AUTOSAR XML (schema 00047)
package /ComponentTypes
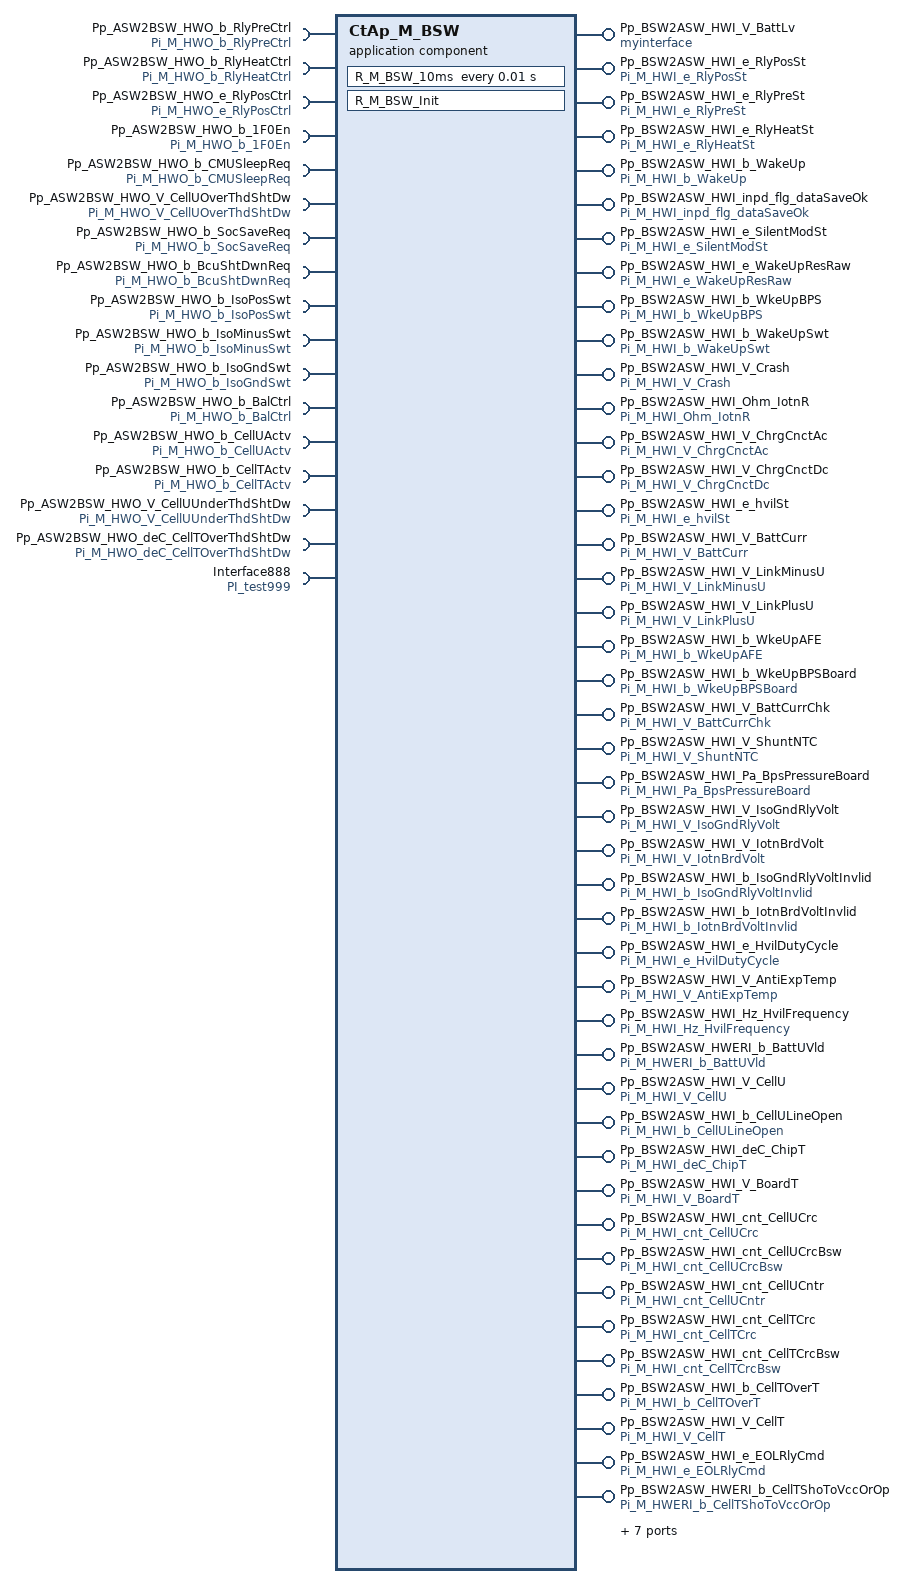
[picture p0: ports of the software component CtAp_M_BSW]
  application sw component type CtAp_M_BSW
    51 x provide port:
      Pp_BSW2ASW_HWI_V_BattLv: nonqueued-sender-com-spec{data-element=HWI_V_BattLv, init-value=123.0}, provided-interface=myinterface
      Pp_BSW2ASW_HWI_e_RlyPosSt: nonqueued-sender-com-spec{data-element=HWI_e_RlyPosSt, init-value=456}, provided-interface=Pi_M_HWI_e_RlyPosSt
      Pp_BSW2ASW_HWI_e_RlyPreSt: nonqueued-sender-com-spec{data-element=HWI_e_RlyPreSt, init-value=0}, provided-interface=Pi_M_HWI_e_RlyPreSt
      Pp_BSW2ASW_HWI_e_RlyHeatSt: nonqueued-sender-com-spec{data-element=HWI_e_RlyHeatSt, init-value=0}, provided-interface=Pi_M_HWI_e_RlyHeatSt
      Pp_BSW2ASW_HWI_b_WakeUp: nonqueued-sender-com-spec{data-element=HWI_b_WakeUp, init-value=0}, provided-interface=Pi_M_HWI_b_WakeUp
      Pp_BSW2ASW_HWI_inpd_flg_dataSaveOk: nonqueued-sender-com-spec{data-element=HWI_inpd_flg_dataSaveOk, init-value=0}, provided-interface=Pi_M_HWI_inpd_flg_dataSaveOk
      Pp_BSW2ASW_HWI_e_SilentModSt: nonqueued-sender-com-spec{data-element=HWI_e_SilentModSt, init-value=0}, provided-interface=Pi_M_HWI_e_SilentModSt
      Pp_BSW2ASW_HWI_e_WakeUpResRaw: nonqueued-sender-com-spec{data-element=HWI_e_WakeUpResRaw, init-value=0}, provided-interface=Pi_M_HWI_e_WakeUpResRaw
      Pp_BSW2ASW_HWI_b_WkeUpBPS: nonqueued-sender-com-spec{data-element=HWI_b_WkeUpBPS, init-value=0}, provided-interface=Pi_M_HWI_b_WkeUpBPS
      Pp_BSW2ASW_HWI_b_WakeUpSwt: nonqueued-sender-com-spec{data-element=HWI_b_WakeUpSwt, init-value=0}, provided-interface=Pi_M_HWI_b_WakeUpSwt
      Pp_BSW2ASW_HWI_V_Crash: nonqueued-sender-com-spec{data-element=HWI_V_Crash, init-value=0.0}, provided-interface=Pi_M_HWI_V_Crash
      Pp_BSW2ASW_HWI_Ohm_IotnR: nonqueued-sender-com-spec{data-element=HWI_Ohm_IotnR, init-value=0}, provided-interface=Pi_M_HWI_Ohm_IotnR
      Pp_BSW2ASW_HWI_V_ChrgCnctAc: nonqueued-sender-com-spec{data-element=HWI_V_ChrgCnctAc, init-value=0.0}, provided-interface=Pi_M_HWI_V_ChrgCnctAc
      Pp_BSW2ASW_HWI_V_ChrgCnctDc: nonqueued-sender-com-spec{data-element=HWI_V_ChrgCnctDc, init-value=0.0}, provided-interface=Pi_M_HWI_V_ChrgCnctDc
      Pp_BSW2ASW_HWI_e_hvilSt: nonqueued-sender-com-spec{data-element=HWI_e_hvilSt, init-value=0}, provided-interface=Pi_M_HWI_e_hvilSt
      Pp_BSW2ASW_HWI_V_BattCurr: nonqueued-sender-com-spec{data-element=HWI_V_BattCurr, init-value=0.0}, provided-interface=Pi_M_HWI_V_BattCurr
      Pp_BSW2ASW_HWI_V_LinkMinusU: nonqueued-sender-com-spec{data-element=HWI_V_LinkMinusU, init-value=0.0}, provided-interface=Pi_M_HWI_V_LinkMinusU
      Pp_BSW2ASW_HWI_V_LinkPlusU: nonqueued-sender-com-spec{data-element=HWI_V_LinkPlusU, init-value=0.0}, provided-interface=Pi_M_HWI_V_LinkPlusU
      Pp_BSW2ASW_HWI_b_WkeUpAFE: nonqueued-sender-com-spec{data-element=HWI_b_WkeUpAFE, init-value=0}, provided-interface=Pi_M_HWI_b_WkeUpAFE
      Pp_BSW2ASW_HWI_b_WkeUpBPSBoard: nonqueued-sender-com-spec{data-element=HWI_b_WkeUpBPSBoard, init-value=0}, provided-interface=Pi_M_HWI_b_WkeUpBPSBoard
      Pp_BSW2ASW_HWI_V_BattCurrChk: nonqueued-sender-com-spec{data-element=HWI_V_BattCurrChk, init-value=0.0}, provided-interface=Pi_M_HWI_V_BattCurrChk
      Pp_BSW2ASW_HWI_V_ShuntNTC: nonqueued-sender-com-spec{data-element=HWI_V_ShuntNTC, init-value=0.0}, provided-interface=Pi_M_HWI_V_ShuntNTC
      Pp_BSW2ASW_HWI_Pa_BpsPressureBoard: nonqueued-sender-com-spec{data-element=HWI_Pa_BpsPressureBoard, init-value=0.0}, provided-interface=Pi_M_HWI_Pa_BpsPressureBoard
      Pp_BSW2ASW_HWI_V_IsoGndRlyVolt: nonqueued-sender-com-spec{data-element=HWI_V_IsoGndRlyVolt, init-value=0.0}, provided-interface=Pi_M_HWI_V_IsoGndRlyVolt
      Pp_BSW2ASW_HWI_V_IotnBrdVolt: nonqueued-sender-com-spec{data-element=HWI_V_IotnBrdVolt, init-value=0.0}, provided-interface=Pi_M_HWI_V_IotnBrdVolt
      Pp_BSW2ASW_HWI_b_IsoGndRlyVoltInvlid: nonqueued-sender-com-spec{data-element=HWI_b_IsoGndRlyVoltInvlid, init-value=0}, provided-interface=Pi_M_HWI_b_IsoGndRlyVoltInvlid
      Pp_BSW2ASW_HWI_b_IotnBrdVoltInvlid: nonqueued-sender-com-spec{data-element=HWI_b_IotnBrdVoltInvlid, init-value=0}, provided-interface=Pi_M_HWI_b_IotnBrdVoltInvlid
      Pp_BSW2ASW_HWI_e_HvilDutyCycle: nonqueued-sender-com-spec{data-element=HWI_e_HvilDutyCycle, init-value=0}, provided-interface=Pi_M_HWI_e_HvilDutyCycle
      Pp_BSW2ASW_HWI_V_AntiExpTemp: nonqueued-sender-com-spec{data-element=HWI_V_AntiExpTemp, init-value=0.0}, provided-interface=Pi_M_HWI_V_AntiExpTemp
      Pp_BSW2ASW_HWI_Hz_HvilFrequency: nonqueued-sender-com-spec{data-element=HWI_Hz_HvilFrequency, init-value=0}, provided-interface=Pi_M_HWI_Hz_HvilFrequency
      Pp_BSW2ASW_HWERI_b_BattUVld: nonqueued-sender-com-spec{data-element=HWERI_b_BattUVld, init-value=0}, provided-interface=Pi_M_HWERI_b_BattUVld
      Pp_BSW2ASW_HWI_V_CellU: nonqueued-sender-com-spec{data-element=HWI_V_CellU, init-value=208 x 11111}, provided-interface=Pi_M_HWI_V_CellU
      Pp_BSW2ASW_HWI_b_CellULineOpen: nonqueued-sender-com-spec{data-element=HWI_b_CellULineOpen, init-value=208 x 22222}, provided-interface=Pi_M_HWI_b_CellULineOpen
      Pp_BSW2ASW_HWI_deC_ChipT: nonqueued-sender-com-spec{data-element=HWI_deC_ChipT, init-value=13 x 33333}, provided-interface=Pi_M_HWI_deC_ChipT
      Pp_BSW2ASW_HWI_V_BoardT: nonqueued-sender-com-spec{data-element=HWI_V_BoardT, init-value=26 x 0}, provided-interface=Pi_M_HWI_V_BoardT
      Pp_BSW2ASW_HWI_cnt_CellUCrc: nonqueued-sender-com-spec{data-element=HWI_cnt_CellUCrc, init-value=208 x 0}, provided-interface=Pi_M_HWI_cnt_CellUCrc
      Pp_BSW2ASW_HWI_cnt_CellUCrcBsw: nonqueued-sender-com-spec{data-element=HWI_cnt_CellUCrcBsw, init-value=208 x 0}, provided-interface=Pi_M_HWI_cnt_CellUCrcBsw
      Pp_BSW2ASW_HWI_cnt_CellUCntr: nonqueued-sender-com-spec{data-element=HWI_cnt_CellUCntr, init-value=208 x 0}, provided-interface=Pi_M_HWI_cnt_CellUCntr
      Pp_BSW2ASW_HWI_cnt_CellTCrc: nonqueued-sender-com-spec{data-element=HWI_cnt_CellTCrc, init-value=78 x 0}, provided-interface=Pi_M_HWI_cnt_CellTCrc
      Pp_BSW2ASW_HWI_cnt_CellTCrcBsw: nonqueued-sender-com-spec{data-element=HWI_cnt_CellTCrcBsw, init-value=78 x 0}, provided-interface=Pi_M_HWI_cnt_CellTCrcBsw
      Pp_BSW2ASW_HWI_b_CellTOverT: nonqueued-sender-com-spec{data-element=HWI_b_CellTOverT, init-value=78 x 0}, provided-interface=Pi_M_HWI_b_CellTOverT
      Pp_BSW2ASW_HWI_V_CellT: nonqueued-sender-com-spec{data-element=HWI_V_CellT, init-value=78 x 0}, provided-interface=Pi_M_HWI_V_CellT
      Pp_BSW2ASW_HWI_e_EOLRlyCmd: nonqueued-sender-com-spec{data-element=HWI_e_EOLRlyCmd, init-value=8 x 0}, provided-interface=Pi_M_HWI_e_EOLRlyCmd
      Pp_BSW2ASW_HWERI_b_CellTShoToVccOrOp: nonqueued-sender-com-spec{data-element=HWERI_b_CellTShoToVccOrOp, init-value=78 x 0}, provided-interface=Pi_M_HWERI_b_CellTShoToVccOrOp
      Pp_BSW2ASW_HWERI_b_CellTShoToGnd: nonqueued-sender-com-spec{data-element=HWERI_b_CellTShoToGnd, init-value=78 x 0}, provided-interface=Pi_M_HWERI_b_CellTShoToGnd
      Pp_BSW2ASW_HWERI_b_CellBalErr: nonqueued-sender-com-spec{data-element=HWERI_b_CellBalErr, init-value=208 x 0}, provided-interface=Pi_M_HWERI_b_CellBalErr
      Pp_BSW2ASW_HWERI_b_CellUOverU: nonqueued-sender-com-spec{data-element=HWERI_b_CellUOverU, init-value=208 x 0}, provided-interface=Pi_M_HWERI_b_CellUOverU
      Pp_BSW2ASW_HWERI_b_CellUUnderU: nonqueued-sender-com-spec{data-element=HWERI_b_CellUUnderU, init-value=208 x 0}, provided-interface=Pi_M_HWERI_b_CellUUnderU
      Pp_BSW2ASW_HWERI_b_ChipComErr: nonqueued-sender-com-spec{data-element=HWERI_b_ChipComErr, init-value=13 x 0}, provided-interface=Pi_M_HWERI_b_ChipComErr
      Pp_BSW2ASW_HWERI_b_SysRstErr: nonqueued-sender-com-spec{data-element=HWERI_b_SysRstErr, init-value=13 x 0}, provided-interface=Pi_M_HWERI_b_SysRstErr
      Pp_BSW2ASW_AccRateType: nonqueued-sender-com-spec{data-element=AccRateType, init-value=fields=[fields=[99.99, 99.99, 99.99], fields=[99.99, 99.99, 99.99]]}, provided-interface=Pi_M_AccRateType
    17 x require port:
      Pp_ASW2BSW_HWO_b_RlyPreCtrl: nonqueued-receiver-com-spec{data-element=HWO_b_RlyPreCtrl, filter=data-filter-type=ALWAYS}, required-interface=Pi_M_HWO_b_RlyPreCtrl
      Pp_ASW2BSW_HWO_b_RlyHeatCtrl: nonqueued-receiver-com-spec{data-element=HWO_b_RlyHeatCtrl, filter=data-filter-type=ALWAYS}, required-interface=Pi_M_HWO_b_RlyHeatCtrl
      Pp_ASW2BSW_HWO_e_RlyPosCtrl: nonqueued-receiver-com-spec{data-element=HWO_e_RlyPosCtrl, filter=data-filter-type=ALWAYS}, required-interface=Pi_M_HWO_e_RlyPosCtrl
      Pp_ASW2BSW_HWO_b_1F0En: nonqueued-receiver-com-spec{data-element=HWO_b_1F0En, filter=data-filter-type=ALWAYS}, required-interface=Pi_M_HWO_b_1F0En
      Pp_ASW2BSW_HWO_b_CMUSleepReq: nonqueued-receiver-com-spec{data-element=HWO_b_CMUSleepReq, filter=data-filter-type=ALWAYS}, required-interface=Pi_M_HWO_b_CMUSleepReq
      Pp_ASW2BSW_HWO_V_CellUOverThdShtDw: nonqueued-receiver-com-spec{data-element=HWO_V_CellUOverThdShtDw, filter=data-filter-type=ALWAYS}, required-interface=Pi_M_HWO_V_CellUOverThdShtDw
      Pp_ASW2BSW_HWO_b_SocSaveReq: nonqueued-receiver-com-spec{data-element=HWO_b_SocSaveReq, filter=data-filter-type=ALWAYS}, required-interface=Pi_M_HWO_b_SocSaveReq
      Pp_ASW2BSW_HWO_b_BcuShtDwnReq: nonqueued-receiver-com-spec{data-element=HWO_b_BcuShtDwnReq, filter=data-filter-type=ALWAYS}, required-interface=Pi_M_HWO_b_BcuShtDwnReq
      Pp_ASW2BSW_HWO_b_IsoPosSwt: nonqueued-receiver-com-spec{data-element=HWO_b_IsoPosSwt, filter=data-filter-type=ALWAYS}, required-interface=Pi_M_HWO_b_IsoPosSwt
      Pp_ASW2BSW_HWO_b_IsoMinusSwt: nonqueued-receiver-com-spec{data-element=HWO_b_IsoMinusSwt, filter=data-filter-type=ALWAYS}, required-interface=Pi_M_HWO_b_IsoMinusSwt
      Pp_ASW2BSW_HWO_b_IsoGndSwt: nonqueued-receiver-com-spec{data-element=HWO_b_IsoGndSwt, filter=data-filter-type=ALWAYS}, required-interface=Pi_M_HWO_b_IsoGndSwt
      Pp_ASW2BSW_HWO_b_BalCtrl: nonqueued-receiver-com-spec{data-element=HWO_b_BalCtrl, filter=data-filter-type=ALWAYS}, required-interface=Pi_M_HWO_b_BalCtrl
      Pp_ASW2BSW_HWO_b_CellUActv: nonqueued-receiver-com-spec{data-element=HWO_b_CellUActv, filter=data-filter-type=ALWAYS}, required-interface=Pi_M_HWO_b_CellUActv
      Pp_ASW2BSW_HWO_b_CellTActv: nonqueued-receiver-com-spec{data-element=HWO_b_CellTActv, filter=data-filter-type=ALWAYS}, required-interface=Pi_M_HWO_b_CellTActv
      Pp_ASW2BSW_HWO_V_CellUUnderThdShtDw: nonqueued-receiver-com-spec{data-element=HWO_V_CellUUnderThdShtDw, filter=data-filter-type=ALWAYS}, required-interface=Pi_M_HWO_V_CellUUnderThdShtDw
      Pp_ASW2BSW_HWO_deC_CellTOverThdShtDw: nonqueued-receiver-com-spec{data-element=HWO_deC_CellTOverThdShtDw, filter=data-filter-type=ALWAYS}, required-interface=Pi_M_HWO_deC_CellTOverThdShtDw
      Interface888: nonqueued-receiver-com-spec{data-element=AccRateArray, filter=data-filter-type=ALWAYS}, required-interface=PI_test999
    behavior CtAp_M_BSW_InternalBehavior
      timing event TMT_R_M_BSW_10ms: start-on-event=R_M_BSW_10ms, period=0.01
      init event TMT_R_M_BSW_InitEvent: start-on-event=R_M_BSW_Init
      runnable R_M_BSW_Init
      runnable R_M_BSW_10ms
        data-receive-point-by-arguments:
          17 x access:
            DRPA_M_HWO_b_RlyPreCtrl_0: accessed-variable=Pp_ASW2BSW_HWO_b_RlyPreCtrl.HWO_b_RlyPreCtrl
            DRPA_M_HWO_b_RlyHeatCtrl_0: accessed-variable=Pp_ASW2BSW_HWO_b_RlyHeatCtrl.HWO_b_RlyHeatCtrl
            DRPA_M_HWO_e_RlyPosCtrl_0: accessed-variable=Pp_ASW2BSW_HWO_e_RlyPosCtrl.HWO_e_RlyPosCtrl
            DRPA_M_HWO_b_1F0En_0: accessed-variable=Pp_ASW2BSW_HWO_b_1F0En.HWO_b_1F0En
            DRPA_M_HWO_b_CMUSleepReq_0: accessed-variable=Pp_ASW2BSW_HWO_b_CMUSleepReq.HWO_b_CMUSleepReq
            DRPA_M_HWO_V_CellUOverThdShtDw_0: accessed-variable=Pp_ASW2BSW_HWO_V_CellUOverThdShtDw.HWO_V_CellUOverThdShtDw
            DRPA_M_HWO_b_SocSaveReq_0: accessed-variable=Pp_ASW2BSW_HWO_b_SocSaveReq.HWO_b_SocSaveReq
            DRPA_M_HWO_b_BcuShtDwnReq_0: accessed-variable=Pp_ASW2BSW_HWO_b_BcuShtDwnReq.HWO_b_BcuShtDwnReq
            DRPA_M_HWO_b_IsoPosSwt_0: accessed-variable=Pp_ASW2BSW_HWO_b_IsoPosSwt.HWO_b_IsoPosSwt
            DRPA_M_HWO_b_IsoMinusSwt_0: accessed-variable=Pp_ASW2BSW_HWO_b_IsoMinusSwt.HWO_b_IsoMinusSwt
            DRPA_M_HWO_b_IsoGndSwt_0: accessed-variable=Pp_ASW2BSW_HWO_b_IsoGndSwt.HWO_b_IsoGndSwt
            DRPA_M_HWO_b_BalCtrl_0: accessed-variable=Pp_ASW2BSW_HWO_b_BalCtrl.HWO_b_BalCtrl
            DRPA_M_HWO_b_CellUActv_0: accessed-variable=Pp_ASW2BSW_HWO_b_CellUActv.HWO_b_CellUActv
            DRPA_M_HWO_b_CellTActv_0: accessed-variable=Pp_ASW2BSW_HWO_b_CellTActv.HWO_b_CellTActv
            DRPA_M_HWO_V_CellUUnderThdShtDw_0: accessed-variable=Pp_ASW2BSW_HWO_V_CellUUnderThdShtDw.HWO_V_CellUUnderThdShtDw
            DRPA_M_HWO_deC_CellTOverThdShtDw_0: accessed-variable=Pp_ASW2BSW_HWO_deC_CellTOverThdShtDw.HWO_deC_CellTOverThdShtDw
            DRPA_M_AccRateArray_0: accessed-variable=Interface888.AccRateArray
        data-send-points:
          51 x access:
            DSP_M_HWI_V_BattLv_0: accessed-variable=Pp_BSW2ASW_HWI_V_BattLv.HWI_V_BattLv
            DSP_M_HWI_e_RlyPosSt_0: accessed-variable=Pp_BSW2ASW_HWI_e_RlyPosSt.HWI_e_RlyPosSt
            DSP_M_HWI_e_RlyPreSt_0: accessed-variable=Pp_BSW2ASW_HWI_e_RlyPreSt.HWI_e_RlyPreSt
            DSP_M_HWI_e_RlyHeatSt_0: accessed-variable=Pp_BSW2ASW_HWI_e_RlyHeatSt.HWI_e_RlyHeatSt
            DSP_M_HWI_b_WakeUp_0: accessed-variable=Pp_BSW2ASW_HWI_b_WakeUp.HWI_b_WakeUp
            DSP_M_HWI_inpd_flg_dataSaveOk_0: accessed-variable=Pp_BSW2ASW_HWI_inpd_flg_dataSaveOk.HWI_inpd_flg_dataSaveOk
            DSP_M_HWI_e_SilentModSt_0: accessed-variable=Pp_BSW2ASW_HWI_e_SilentModSt.HWI_e_SilentModSt
            DSP_M_HWI_e_WakeUpResRaw_0: accessed-variable=Pp_BSW2ASW_HWI_e_WakeUpResRaw.HWI_e_WakeUpResRaw
            DSP_M_HWI_b_WkeUpBPS_0: accessed-variable=Pp_BSW2ASW_HWI_b_WkeUpBPS.HWI_b_WkeUpBPS
            DSP_M_HWI_b_WakeUpSwt_0: accessed-variable=Pp_BSW2ASW_HWI_b_WakeUpSwt.HWI_b_WakeUpSwt
            DSP_M_HWI_V_Crash_0: accessed-variable=Pp_BSW2ASW_HWI_V_Crash.HWI_V_Crash
            DSP_M_HWI_Ohm_IotnR_0: accessed-variable=Pp_BSW2ASW_HWI_Ohm_IotnR.HWI_Ohm_IotnR
            DSP_M_HWI_V_ChrgCnctAc_0: accessed-variable=Pp_BSW2ASW_HWI_V_ChrgCnctAc.HWI_V_ChrgCnctAc
            DSP_M_HWI_V_ChrgCnctDc_0: accessed-variable=Pp_BSW2ASW_HWI_V_ChrgCnctDc.HWI_V_ChrgCnctDc
            DSP_M_HWI_e_hvilSt_0: accessed-variable=Pp_BSW2ASW_HWI_e_hvilSt.HWI_e_hvilSt
            DSP_M_HWI_V_BattCurr_0: accessed-variable=Pp_BSW2ASW_HWI_V_BattCurr.HWI_V_BattCurr
            DSP_M_HWI_V_LinkMinusU_0: accessed-variable=Pp_BSW2ASW_HWI_V_LinkMinusU.HWI_V_LinkMinusU
            DSP_M_HWI_V_LinkPlusU_0: accessed-variable=Pp_BSW2ASW_HWI_V_LinkPlusU.HWI_V_LinkPlusU
            DSP_M_HWI_b_WkeUpAFE_0: accessed-variable=Pp_BSW2ASW_HWI_b_WkeUpAFE.HWI_b_WkeUpAFE
            DSP_M_HWI_b_WkeUpBPSBoard_0: accessed-variable=Pp_BSW2ASW_HWI_b_WkeUpBPSBoard.HWI_b_WkeUpBPSBoard
            DSP_M_HWI_V_BattCurrChk_0: accessed-variable=Pp_BSW2ASW_HWI_V_BattCurrChk.HWI_V_BattCurrChk
            DSP_M_HWI_V_ShuntNTC_0: accessed-variable=Pp_BSW2ASW_HWI_V_ShuntNTC.HWI_V_ShuntNTC
            DSP_M_HWI_Pa_BpsPressureBoard_0: accessed-variable=Pp_BSW2ASW_HWI_Pa_BpsPressureBoard.HWI_Pa_BpsPressureBoard
            DSP_M_HWI_V_IsoGndRlyVolt_0: accessed-variable=Pp_BSW2ASW_HWI_V_IsoGndRlyVolt.HWI_V_IsoGndRlyVolt
            DSP_M_HWI_V_IotnBrdVolt_0: accessed-variable=Pp_BSW2ASW_HWI_V_IotnBrdVolt.HWI_V_IotnBrdVolt
            DSP_M_HWI_b_IsoGndRlyVoltInvlid_0: accessed-variable=Pp_BSW2ASW_HWI_b_IsoGndRlyVoltInvlid.HWI_b_IsoGndRlyVoltInvlid
            DSP_M_HWI_b_IotnBrdVoltInvlid_0: accessed-variable=Pp_BSW2ASW_HWI_b_IotnBrdVoltInvlid.HWI_b_IotnBrdVoltInvlid
            DSP_M_HWI_e_HvilDutyCycle_0: accessed-variable=Pp_BSW2ASW_HWI_e_HvilDutyCycle.HWI_e_HvilDutyCycle
            DSP_M_HWI_V_AntiExpTemp_0: accessed-variable=Pp_BSW2ASW_HWI_V_AntiExpTemp.HWI_V_AntiExpTemp
            DSP_M_HWI_Hz_HvilFrequency_0: accessed-variable=Pp_BSW2ASW_HWI_Hz_HvilFrequency.HWI_Hz_HvilFrequency
            DSP_M_HWERI_b_BattUVld_0: accessed-variable=Pp_BSW2ASW_HWERI_b_BattUVld.HWERI_b_BattUVld
            DSP_M_HWI_V_CellU_0: accessed-variable=Pp_BSW2ASW_HWI_V_CellU.HWI_V_CellU
            DSP_M_HWI_b_CellULineOpen_0: accessed-variable=Pp_BSW2ASW_HWI_b_CellULineOpen.HWI_b_CellULineOpen
            DSP_M_HWI_deC_ChipT_0: accessed-variable=Pp_BSW2ASW_HWI_deC_ChipT.HWI_deC_ChipT
            DSP_M_HWI_V_BoardT_0: accessed-variable=Pp_BSW2ASW_HWI_V_BoardT.HWI_V_BoardT
            DSP_M_HWI_cnt_CellUCrc_0: accessed-variable=Pp_BSW2ASW_HWI_cnt_CellUCrc.HWI_cnt_CellUCrc
            DSP_M_HWI_cnt_CellUCrcBsw_0: accessed-variable=Pp_BSW2ASW_HWI_cnt_CellUCrcBsw.HWI_cnt_CellUCrcBsw
            DSP_M_HWI_cnt_CellUCntr_0: accessed-variable=Pp_BSW2ASW_HWI_cnt_CellUCntr.HWI_cnt_CellUCntr
            DSP_M_HWI_cnt_CellTCrc_0: accessed-variable=Pp_BSW2ASW_HWI_cnt_CellTCrc.HWI_cnt_CellTCrc
            DSP_M_HWI_cnt_CellTCrcBsw_0: accessed-variable=Pp_BSW2ASW_HWI_cnt_CellTCrcBsw.HWI_cnt_CellTCrcBsw
            DSP_M_HWI_b_CellTOverT_0: accessed-variable=Pp_BSW2ASW_HWI_b_CellTOverT.HWI_b_CellTOverT
            DSP_M_HWI_V_CellT_0: accessed-variable=Pp_BSW2ASW_HWI_V_CellT.HWI_V_CellT
            DSP_M_HWI_e_EOLRlyCmd_0: accessed-variable=Pp_BSW2ASW_HWI_e_EOLRlyCmd.HWI_e_EOLRlyCmd
            DSP_M_HWERI_b_CellTShoToVccOrOp_0: accessed-variable=Pp_BSW2ASW_HWERI_b_CellTShoToVccOrOp.HWERI_b_CellTShoToVccOrOp
            DSP_M_HWERI_b_CellTShoToGnd_0: accessed-variable=Pp_BSW2ASW_HWERI_b_CellTShoToGnd.HWERI_b_CellTShoToGnd
            DSP_M_HWERI_b_CellBalErr_0: accessed-variable=Pp_BSW2ASW_HWERI_b_CellBalErr.HWERI_b_CellBalErr
            DSP_M_HWERI_b_CellUOverU_0: accessed-variable=Pp_BSW2ASW_HWERI_b_CellUOverU.HWERI_b_CellUOverU
            DSP_M_HWERI_b_CellUUnderU_0: accessed-variable=Pp_BSW2ASW_HWERI_b_CellUUnderU.HWERI_b_CellUUnderU
            DSP_M_HWERI_b_ChipComErr_0: accessed-variable=Pp_BSW2ASW_HWERI_b_ChipComErr.HWERI_b_ChipComErr
            DSP_M_HWERI_b_SysRstErr_0: accessed-variable=Pp_BSW2ASW_HWERI_b_SysRstErr.HWERI_b_SysRstErr
            DSP_M_AccRateType_0: accessed-variable=Pp_BSW2ASW_AccRateType.AccRateType
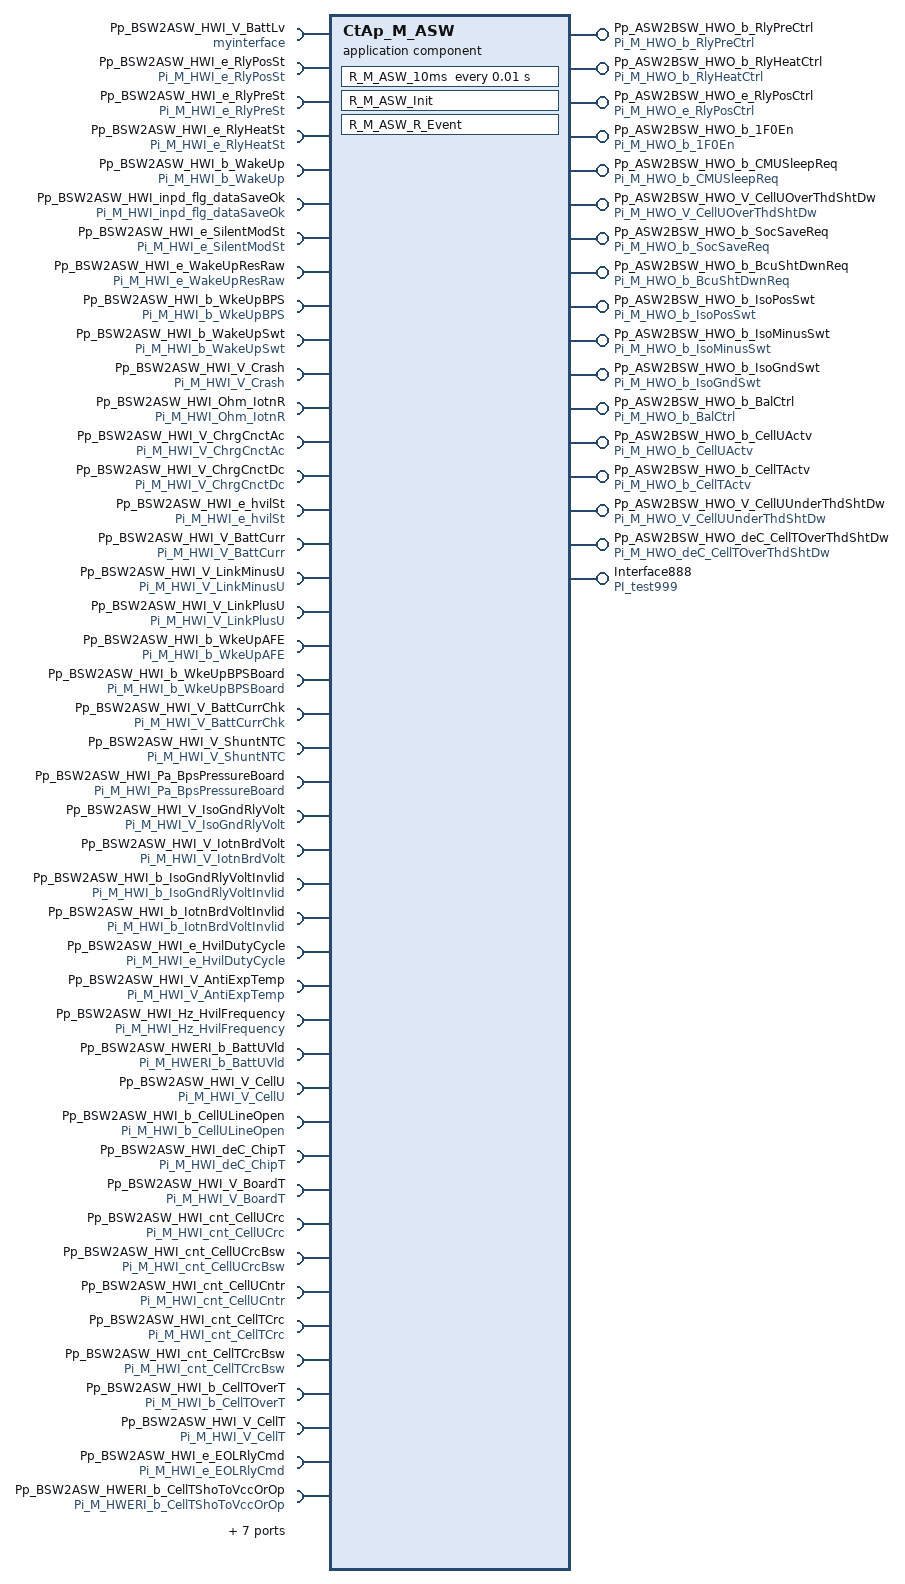
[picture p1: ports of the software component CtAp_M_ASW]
  application sw component type CtAp_M_ASW
    17 x provide port:
      Pp_ASW2BSW_HWO_b_RlyPreCtrl: nonqueued-sender-com-spec{data-element=HWO_b_RlyPreCtrl, init-value=0}, provided-interface=Pi_M_HWO_b_RlyPreCtrl
      Pp_ASW2BSW_HWO_b_RlyHeatCtrl: nonqueued-sender-com-spec{data-element=HWO_b_RlyHeatCtrl, init-value=0}, provided-interface=Pi_M_HWO_b_RlyHeatCtrl
      Pp_ASW2BSW_HWO_e_RlyPosCtrl: nonqueued-sender-com-spec{data-element=HWO_e_RlyPosCtrl, init-value=0}, provided-interface=Pi_M_HWO_e_RlyPosCtrl
      Pp_ASW2BSW_HWO_b_1F0En: nonqueued-sender-com-spec{data-element=HWO_b_1F0En, init-value=0}, provided-interface=Pi_M_HWO_b_1F0En
      Pp_ASW2BSW_HWO_b_CMUSleepReq: nonqueued-sender-com-spec{data-element=HWO_b_CMUSleepReq, init-value=0}, provided-interface=Pi_M_HWO_b_CMUSleepReq
      Pp_ASW2BSW_HWO_V_CellUOverThdShtDw: nonqueued-sender-com-spec{data-element=HWO_V_CellUOverThdShtDw, init-value=0.0}, provided-interface=Pi_M_HWO_V_CellUOverThdShtDw
      Pp_ASW2BSW_HWO_b_SocSaveReq: nonqueued-sender-com-spec{data-element=HWO_b_SocSaveReq, init-value=0}, provided-interface=Pi_M_HWO_b_SocSaveReq
      Pp_ASW2BSW_HWO_b_BcuShtDwnReq: nonqueued-sender-com-spec{data-element=HWO_b_BcuShtDwnReq, init-value=0}, provided-interface=Pi_M_HWO_b_BcuShtDwnReq
      Pp_ASW2BSW_HWO_b_IsoPosSwt: nonqueued-sender-com-spec{data-element=HWO_b_IsoPosSwt, init-value=0}, provided-interface=Pi_M_HWO_b_IsoPosSwt
      Pp_ASW2BSW_HWO_b_IsoMinusSwt: nonqueued-sender-com-spec{data-element=HWO_b_IsoMinusSwt, init-value=0}, provided-interface=Pi_M_HWO_b_IsoMinusSwt
      Pp_ASW2BSW_HWO_b_IsoGndSwt: nonqueued-sender-com-spec{data-element=HWO_b_IsoGndSwt, init-value=0}, provided-interface=Pi_M_HWO_b_IsoGndSwt
      Pp_ASW2BSW_HWO_b_BalCtrl: nonqueued-sender-com-spec{data-element=HWO_b_BalCtrl, init-value=208 x 0}, provided-interface=Pi_M_HWO_b_BalCtrl
      Pp_ASW2BSW_HWO_b_CellUActv: nonqueued-sender-com-spec{data-element=HWO_b_CellUActv, init-value=208 x 0}, provided-interface=Pi_M_HWO_b_CellUActv
      Pp_ASW2BSW_HWO_b_CellTActv: nonqueued-sender-com-spec{data-element=HWO_b_CellTActv, init-value=78 x 0}, provided-interface=Pi_M_HWO_b_CellTActv
      Pp_ASW2BSW_HWO_V_CellUUnderThdShtDw: nonqueued-sender-com-spec{data-element=HWO_V_CellUUnderThdShtDw, init-value=208 x 0}, provided-interface=Pi_M_HWO_V_CellUUnderThdShtDw
      Pp_ASW2BSW_HWO_deC_CellTOverThdShtDw: nonqueued-sender-com-spec{data-element=HWO_deC_CellTOverThdShtDw, init-value=78 x 555}, provided-interface=Pi_M_HWO_deC_CellTOverThdShtDw
      Interface888: nonqueued-sender-com-spec{data-element=AccRateArray, init-value=12 x fields=[fields=[99.99, 99.99, 99.99], fields=[99.99, 99.99, 99.99]]}, provided-interface=PI_test999
    51 x require port:
      Pp_BSW2ASW_HWI_V_BattLv: nonqueued-receiver-com-spec{data-element=HWI_V_BattLv, filter=data-filter-type=ALWAYS}, required-interface=myinterface
      Pp_BSW2ASW_HWI_e_RlyPosSt: nonqueued-receiver-com-spec{data-element=HWI_e_RlyPosSt, filter=data-filter-type=ALWAYS}, required-interface=Pi_M_HWI_e_RlyPosSt
      Pp_BSW2ASW_HWI_e_RlyPreSt: nonqueued-receiver-com-spec{data-element=HWI_e_RlyPreSt, filter=data-filter-type=ALWAYS}, required-interface=Pi_M_HWI_e_RlyPreSt
      Pp_BSW2ASW_HWI_e_RlyHeatSt: nonqueued-receiver-com-spec{data-element=HWI_e_RlyHeatSt, filter=data-filter-type=ALWAYS}, required-interface=Pi_M_HWI_e_RlyHeatSt
      Pp_BSW2ASW_HWI_b_WakeUp: nonqueued-receiver-com-spec{data-element=HWI_b_WakeUp, filter=data-filter-type=ALWAYS}, required-interface=Pi_M_HWI_b_WakeUp
      Pp_BSW2ASW_HWI_inpd_flg_dataSaveOk: nonqueued-receiver-com-spec{data-element=HWI_inpd_flg_dataSaveOk, filter=data-filter-type=ALWAYS}, required-interface=Pi_M_HWI_inpd_flg_dataSaveOk
      Pp_BSW2ASW_HWI_e_SilentModSt: nonqueued-receiver-com-spec{data-element=HWI_e_SilentModSt, filter=data-filter-type=ALWAYS}, required-interface=Pi_M_HWI_e_SilentModSt
      Pp_BSW2ASW_HWI_e_WakeUpResRaw: nonqueued-receiver-com-spec{data-element=HWI_e_WakeUpResRaw, filter=data-filter-type=ALWAYS}, required-interface=Pi_M_HWI_e_WakeUpResRaw
      Pp_BSW2ASW_HWI_b_WkeUpBPS: nonqueued-receiver-com-spec{data-element=HWI_b_WkeUpBPS, filter=data-filter-type=ALWAYS}, required-interface=Pi_M_HWI_b_WkeUpBPS
      Pp_BSW2ASW_HWI_b_WakeUpSwt: nonqueued-receiver-com-spec{data-element=HWI_b_WakeUpSwt, filter=data-filter-type=ALWAYS}, required-interface=Pi_M_HWI_b_WakeUpSwt
      Pp_BSW2ASW_HWI_V_Crash: nonqueued-receiver-com-spec{data-element=HWI_V_Crash, filter=data-filter-type=ALWAYS}, required-interface=Pi_M_HWI_V_Crash
      Pp_BSW2ASW_HWI_Ohm_IotnR: nonqueued-receiver-com-spec{data-element=HWI_Ohm_IotnR, filter=data-filter-type=ALWAYS}, required-interface=Pi_M_HWI_Ohm_IotnR
      Pp_BSW2ASW_HWI_V_ChrgCnctAc: nonqueued-receiver-com-spec{data-element=HWI_V_ChrgCnctAc, filter=data-filter-type=ALWAYS}, required-interface=Pi_M_HWI_V_ChrgCnctAc
      Pp_BSW2ASW_HWI_V_ChrgCnctDc: nonqueued-receiver-com-spec{data-element=HWI_V_ChrgCnctDc, filter=data-filter-type=ALWAYS}, required-interface=Pi_M_HWI_V_ChrgCnctDc
      Pp_BSW2ASW_HWI_e_hvilSt: nonqueued-receiver-com-spec{data-element=HWI_e_hvilSt, filter=data-filter-type=ALWAYS}, required-interface=Pi_M_HWI_e_hvilSt
      Pp_BSW2ASW_HWI_V_BattCurr: nonqueued-receiver-com-spec{data-element=HWI_V_BattCurr, filter=data-filter-type=ALWAYS}, required-interface=Pi_M_HWI_V_BattCurr
      Pp_BSW2ASW_HWI_V_LinkMinusU: nonqueued-receiver-com-spec{data-element=HWI_V_LinkMinusU, filter=data-filter-type=ALWAYS}, required-interface=Pi_M_HWI_V_LinkMinusU
      Pp_BSW2ASW_HWI_V_LinkPlusU: nonqueued-receiver-com-spec{data-element=HWI_V_LinkPlusU, filter=data-filter-type=ALWAYS}, required-interface=Pi_M_HWI_V_LinkPlusU
      Pp_BSW2ASW_HWI_b_WkeUpAFE: nonqueued-receiver-com-spec{data-element=HWI_b_WkeUpAFE, filter=data-filter-type=ALWAYS}, required-interface=Pi_M_HWI_b_WkeUpAFE
      Pp_BSW2ASW_HWI_b_WkeUpBPSBoard: nonqueued-receiver-com-spec{data-element=HWI_b_WkeUpBPSBoard, filter=data-filter-type=ALWAYS}, required-interface=Pi_M_HWI_b_WkeUpBPSBoard
      Pp_BSW2ASW_HWI_V_BattCurrChk: nonqueued-receiver-com-spec{data-element=HWI_V_BattCurrChk, filter=data-filter-type=ALWAYS}, required-interface=Pi_M_HWI_V_BattCurrChk
      Pp_BSW2ASW_HWI_V_ShuntNTC: nonqueued-receiver-com-spec{data-element=HWI_V_ShuntNTC, filter=data-filter-type=ALWAYS}, required-interface=Pi_M_HWI_V_ShuntNTC
      Pp_BSW2ASW_HWI_Pa_BpsPressureBoard: nonqueued-receiver-com-spec{data-element=HWI_Pa_BpsPressureBoard, filter=data-filter-type=ALWAYS}, required-interface=Pi_M_HWI_Pa_BpsPressureBoard
      Pp_BSW2ASW_HWI_V_IsoGndRlyVolt: nonqueued-receiver-com-spec{data-element=HWI_V_IsoGndRlyVolt, filter=data-filter-type=ALWAYS}, required-interface=Pi_M_HWI_V_IsoGndRlyVolt
      Pp_BSW2ASW_HWI_V_IotnBrdVolt: nonqueued-receiver-com-spec{data-element=HWI_V_IotnBrdVolt, filter=data-filter-type=ALWAYS}, required-interface=Pi_M_HWI_V_IotnBrdVolt
      Pp_BSW2ASW_HWI_b_IsoGndRlyVoltInvlid: nonqueued-receiver-com-spec{data-element=HWI_b_IsoGndRlyVoltInvlid, filter=data-filter-type=ALWAYS}, required-interface=Pi_M_HWI_b_IsoGndRlyVoltInvlid
      Pp_BSW2ASW_HWI_b_IotnBrdVoltInvlid: nonqueued-receiver-com-spec{data-element=HWI_b_IotnBrdVoltInvlid, filter=data-filter-type=ALWAYS}, required-interface=Pi_M_HWI_b_IotnBrdVoltInvlid
      Pp_BSW2ASW_HWI_e_HvilDutyCycle: nonqueued-receiver-com-spec{data-element=HWI_e_HvilDutyCycle, filter=data-filter-type=ALWAYS}, required-interface=Pi_M_HWI_e_HvilDutyCycle
      Pp_BSW2ASW_HWI_V_AntiExpTemp: nonqueued-receiver-com-spec{data-element=HWI_V_AntiExpTemp, filter=data-filter-type=ALWAYS}, required-interface=Pi_M_HWI_V_AntiExpTemp
      Pp_BSW2ASW_HWI_Hz_HvilFrequency: nonqueued-receiver-com-spec{data-element=HWI_Hz_HvilFrequency, filter=data-filter-type=ALWAYS}, required-interface=Pi_M_HWI_Hz_HvilFrequency
      Pp_BSW2ASW_HWERI_b_BattUVld: nonqueued-receiver-com-spec{data-element=HWERI_b_BattUVld, filter=data-filter-type=ALWAYS}, required-interface=Pi_M_HWERI_b_BattUVld
      Pp_BSW2ASW_HWI_V_CellU: nonqueued-receiver-com-spec{data-element=HWI_V_CellU, filter=data-filter-type=ALWAYS}, required-interface=Pi_M_HWI_V_CellU
      Pp_BSW2ASW_HWI_b_CellULineOpen: nonqueued-receiver-com-spec{data-element=HWI_b_CellULineOpen, filter=data-filter-type=ALWAYS}, required-interface=Pi_M_HWI_b_CellULineOpen
      Pp_BSW2ASW_HWI_deC_ChipT: nonqueued-receiver-com-spec{data-element=HWI_deC_ChipT, filter=data-filter-type=ALWAYS}, required-interface=Pi_M_HWI_deC_ChipT
      Pp_BSW2ASW_HWI_V_BoardT: nonqueued-receiver-com-spec{data-element=HWI_V_BoardT, filter=data-filter-type=ALWAYS}, required-interface=Pi_M_HWI_V_BoardT
      Pp_BSW2ASW_HWI_cnt_CellUCrc: nonqueued-receiver-com-spec{data-element=HWI_cnt_CellUCrc, filter=data-filter-type=ALWAYS}, required-interface=Pi_M_HWI_cnt_CellUCrc
      Pp_BSW2ASW_HWI_cnt_CellUCrcBsw: nonqueued-receiver-com-spec{data-element=HWI_cnt_CellUCrcBsw, filter=data-filter-type=ALWAYS}, required-interface=Pi_M_HWI_cnt_CellUCrcBsw
      Pp_BSW2ASW_HWI_cnt_CellUCntr: nonqueued-receiver-com-spec{data-element=HWI_cnt_CellUCntr, filter=data-filter-type=ALWAYS}, required-interface=Pi_M_HWI_cnt_CellUCntr
      Pp_BSW2ASW_HWI_cnt_CellTCrc: nonqueued-receiver-com-spec{data-element=HWI_cnt_CellTCrc, filter=data-filter-type=ALWAYS}, required-interface=Pi_M_HWI_cnt_CellTCrc
      Pp_BSW2ASW_HWI_cnt_CellTCrcBsw: nonqueued-receiver-com-spec{data-element=HWI_cnt_CellTCrcBsw, filter=data-filter-type=ALWAYS}, required-interface=Pi_M_HWI_cnt_CellTCrcBsw
      Pp_BSW2ASW_HWI_b_CellTOverT: nonqueued-receiver-com-spec{data-element=HWI_b_CellTOverT, filter=data-filter-type=ALWAYS}, required-interface=Pi_M_HWI_b_CellTOverT
      Pp_BSW2ASW_HWI_V_CellT: nonqueued-receiver-com-spec{data-element=HWI_V_CellT, filter=data-filter-type=ALWAYS}, required-interface=Pi_M_HWI_V_CellT
      Pp_BSW2ASW_HWI_e_EOLRlyCmd: nonqueued-receiver-com-spec{data-element=HWI_e_EOLRlyCmd, filter=data-filter-type=ALWAYS}, required-interface=Pi_M_HWI_e_EOLRlyCmd
      Pp_BSW2ASW_HWERI_b_CellTShoToVccOrOp: nonqueued-receiver-com-spec{data-element=HWERI_b_CellTShoToVccOrOp, filter=data-filter-type=ALWAYS}, required-interface=Pi_M_HWERI_b_CellTShoToVccOrOp
      Pp_BSW2ASW_HWERI_b_CellTShoToGnd: nonqueued-receiver-com-spec{data-element=HWERI_b_CellTShoToGnd, filter=data-filter-type=ALWAYS}, required-interface=Pi_M_HWERI_b_CellTShoToGnd
      Pp_BSW2ASW_HWERI_b_CellBalErr: nonqueued-receiver-com-spec{data-element=HWERI_b_CellBalErr, filter=data-filter-type=ALWAYS}, required-interface=Pi_M_HWERI_b_CellBalErr
      Pp_BSW2ASW_HWERI_b_CellUOverU: nonqueued-receiver-com-spec{data-element=HWERI_b_CellUOverU, filter=data-filter-type=ALWAYS}, required-interface=Pi_M_HWERI_b_CellUOverU
      Pp_BSW2ASW_HWERI_b_CellUUnderU: nonqueued-receiver-com-spec{data-element=HWERI_b_CellUUnderU, filter=data-filter-type=ALWAYS}, required-interface=Pi_M_HWERI_b_CellUUnderU
      Pp_BSW2ASW_HWERI_b_ChipComErr: nonqueued-receiver-com-spec{data-element=HWERI_b_ChipComErr, filter=data-filter-type=ALWAYS}, required-interface=Pi_M_HWERI_b_ChipComErr
      Pp_BSW2ASW_HWERI_b_SysRstErr: nonqueued-receiver-com-spec{data-element=HWERI_b_SysRstErr, filter=data-filter-type=ALWAYS}, required-interface=Pi_M_HWERI_b_SysRstErr
      Pp_BSW2ASW_AccRateType: nonqueued-receiver-com-spec{data-element=AccRateType, filter=data-filter-type=ALWAYS}, required-interface=Pi_M_AccRateType
    behavior CtAp_M_ASW_InternalBehavior
      timing event TMT_R_M_ASW_10ms: start-on-event=R_M_ASW_10ms, period=0.01
      init event TMT_R_M_ASW_InitEvent: start-on-event=R_M_ASW_Init
      data received event TMT_R_M_ASW_R_Event_1: start-on-event=R_M_ASW_R_Event, data=Pp_BSW2ASW_HWI_V_CellU.HWI_V_CellU
      runnable R_M_ASW_Init
      runnable R_M_ASW_10ms
        data-receive-point-by-arguments:
          50 x access:
            DRPA_M_HWI_V_BattLv_0: accessed-variable=Pp_BSW2ASW_HWI_V_BattLv.HWI_V_BattLv
            DRPA_M_HWI_e_RlyPosSt_0: accessed-variable=Pp_BSW2ASW_HWI_e_RlyPosSt.HWI_e_RlyPosSt
            DRPA_M_HWI_e_RlyPreSt_0: accessed-variable=Pp_BSW2ASW_HWI_e_RlyPreSt.HWI_e_RlyPreSt
            DRPA_M_HWI_e_RlyHeatSt_0: accessed-variable=Pp_BSW2ASW_HWI_e_RlyHeatSt.HWI_e_RlyHeatSt
            DRPA_M_HWI_b_WakeUp_0: accessed-variable=Pp_BSW2ASW_HWI_b_WakeUp.HWI_b_WakeUp
            DRPA_M_HWI_inpd_flg_dataSaveOk_0: accessed-variable=Pp_BSW2ASW_HWI_inpd_flg_dataSaveOk.HWI_inpd_flg_dataSaveOk
            DRPA_M_HWI_e_SilentModSt_0: accessed-variable=Pp_BSW2ASW_HWI_e_SilentModSt.HWI_e_SilentModSt
            DRPA_M_HWI_e_WakeUpResRaw_0: accessed-variable=Pp_BSW2ASW_HWI_e_WakeUpResRaw.HWI_e_WakeUpResRaw
            DRPA_M_HWI_b_WkeUpBPS_0: accessed-variable=Pp_BSW2ASW_HWI_b_WkeUpBPS.HWI_b_WkeUpBPS
            DRPA_M_HWI_b_WakeUpSwt_0: accessed-variable=Pp_BSW2ASW_HWI_b_WakeUpSwt.HWI_b_WakeUpSwt
            DRPA_M_HWI_V_Crash_0: accessed-variable=Pp_BSW2ASW_HWI_V_Crash.HWI_V_Crash
            DRPA_M_HWI_Ohm_IotnR_0: accessed-variable=Pp_BSW2ASW_HWI_Ohm_IotnR.HWI_Ohm_IotnR
            DRPA_M_HWI_V_ChrgCnctAc_0: accessed-variable=Pp_BSW2ASW_HWI_V_ChrgCnctAc.HWI_V_ChrgCnctAc
            DRPA_M_HWI_V_ChrgCnctDc_0: accessed-variable=Pp_BSW2ASW_HWI_V_ChrgCnctDc.HWI_V_ChrgCnctDc
            DRPA_M_HWI_e_hvilSt_0: accessed-variable=Pp_BSW2ASW_HWI_e_hvilSt.HWI_e_hvilSt
            DRPA_M_HWI_V_BattCurr_0: accessed-variable=Pp_BSW2ASW_HWI_V_BattCurr.HWI_V_BattCurr
            DRPA_M_HWI_V_LinkMinusU_0: accessed-variable=Pp_BSW2ASW_HWI_V_LinkMinusU.HWI_V_LinkMinusU
            DRPA_M_HWI_V_LinkPlusU_0: accessed-variable=Pp_BSW2ASW_HWI_V_LinkPlusU.HWI_V_LinkPlusU
            DRPA_M_HWI_b_WkeUpAFE_0: accessed-variable=Pp_BSW2ASW_HWI_b_WkeUpAFE.HWI_b_WkeUpAFE
            DRPA_M_HWI_b_WkeUpBPSBoard_0: accessed-variable=Pp_BSW2ASW_HWI_b_WkeUpBPSBoard.HWI_b_WkeUpBPSBoard
            DRPA_M_HWI_V_BattCurrChk_0: accessed-variable=Pp_BSW2ASW_HWI_V_BattCurrChk.HWI_V_BattCurrChk
            DRPA_M_HWI_V_ShuntNTC_0: accessed-variable=Pp_BSW2ASW_HWI_V_ShuntNTC.HWI_V_ShuntNTC
            DRPA_M_HWI_Pa_BpsPressureBoard_0: accessed-variable=Pp_BSW2ASW_HWI_Pa_BpsPressureBoard.HWI_Pa_BpsPressureBoard
            DRPA_M_HWI_V_IsoGndRlyVolt_0: accessed-variable=Pp_BSW2ASW_HWI_V_IsoGndRlyVolt.HWI_V_IsoGndRlyVolt
            DRPA_M_HWI_V_IotnBrdVolt_0: accessed-variable=Pp_BSW2ASW_HWI_V_IotnBrdVolt.HWI_V_IotnBrdVolt
            DRPA_M_HWI_b_IsoGndRlyVoltInvlid_0: accessed-variable=Pp_BSW2ASW_HWI_b_IsoGndRlyVoltInvlid.HWI_b_IsoGndRlyVoltInvlid
            DRPA_M_HWI_b_IotnBrdVoltInvlid_0: accessed-variable=Pp_BSW2ASW_HWI_b_IotnBrdVoltInvlid.HWI_b_IotnBrdVoltInvlid
            DRPA_M_HWI_e_HvilDutyCycle_0: accessed-variable=Pp_BSW2ASW_HWI_e_HvilDutyCycle.HWI_e_HvilDutyCycle
            DRPA_M_HWI_V_AntiExpTemp_0: accessed-variable=Pp_BSW2ASW_HWI_V_AntiExpTemp.HWI_V_AntiExpTemp
            DRPA_M_HWI_Hz_HvilFrequency_0: accessed-variable=Pp_BSW2ASW_HWI_Hz_HvilFrequency.HWI_Hz_HvilFrequency
            DRPA_M_HWERI_b_BattUVld_0: accessed-variable=Pp_BSW2ASW_HWERI_b_BattUVld.HWERI_b_BattUVld
            DRPA_M_HWI_b_CellULineOpen_0: accessed-variable=Pp_BSW2ASW_HWI_b_CellULineOpen.HWI_b_CellULineOpen
            DRPA_M_HWI_deC_ChipT_0: accessed-variable=Pp_BSW2ASW_HWI_deC_ChipT.HWI_deC_ChipT
            DRPA_M_HWI_V_BoardT_0: accessed-variable=Pp_BSW2ASW_HWI_V_BoardT.HWI_V_BoardT
            DRPA_M_HWI_cnt_CellUCrc_0: accessed-variable=Pp_BSW2ASW_HWI_cnt_CellUCrc.HWI_cnt_CellUCrc
            DRPA_M_HWI_cnt_CellUCrcBsw_0: accessed-variable=Pp_BSW2ASW_HWI_cnt_CellUCrcBsw.HWI_cnt_CellUCrcBsw
            DRPA_M_HWI_cnt_CellUCntr_0: accessed-variable=Pp_BSW2ASW_HWI_cnt_CellUCntr.HWI_cnt_CellUCntr
            DRPA_M_HWI_cnt_CellTCrc_0: accessed-variable=Pp_BSW2ASW_HWI_cnt_CellTCrc.HWI_cnt_CellTCrc
            DRPA_M_HWI_cnt_CellTCrcBsw_0: accessed-variable=Pp_BSW2ASW_HWI_cnt_CellTCrcBsw.HWI_cnt_CellTCrcBsw
            DRPA_M_HWI_b_CellTOverT_0: accessed-variable=Pp_BSW2ASW_HWI_b_CellTOverT.HWI_b_CellTOverT
            DRPA_M_HWI_V_CellT_0: accessed-variable=Pp_BSW2ASW_HWI_V_CellT.HWI_V_CellT
            DRPA_M_HWI_e_EOLRlyCmd_0: accessed-variable=Pp_BSW2ASW_HWI_e_EOLRlyCmd.HWI_e_EOLRlyCmd
            DRPA_M_HWERI_b_CellTShoToVccOrOp_0: accessed-variable=Pp_BSW2ASW_HWERI_b_CellTShoToVccOrOp.HWERI_b_CellTShoToVccOrOp
            DRPA_M_HWERI_b_CellTShoToGnd_0: accessed-variable=Pp_BSW2ASW_HWERI_b_CellTShoToGnd.HWERI_b_CellTShoToGnd
            DRPA_M_HWERI_b_CellBalErr_0: accessed-variable=Pp_BSW2ASW_HWERI_b_CellBalErr.HWERI_b_CellBalErr
            DRPA_M_HWERI_b_CellUOverU_0: accessed-variable=Pp_BSW2ASW_HWERI_b_CellUOverU.HWERI_b_CellUOverU
            DRPA_M_HWERI_b_CellUUnderU_0: accessed-variable=Pp_BSW2ASW_HWERI_b_CellUUnderU.HWERI_b_CellUUnderU
            DRPA_M_HWERI_b_ChipComErr_0: accessed-variable=Pp_BSW2ASW_HWERI_b_ChipComErr.HWERI_b_ChipComErr
            DRPA_M_HWERI_b_SysRstErr_0: accessed-variable=Pp_BSW2ASW_HWERI_b_SysRstErr.HWERI_b_SysRstErr
            DRPA_M_AccRateType_0: accessed-variable=Pp_BSW2ASW_AccRateType.AccRateType
        data-send-points:
          17 x access:
            DSP_M_HWO_b_RlyPreCtrl_0: accessed-variable=Pp_ASW2BSW_HWO_b_RlyPreCtrl.HWO_b_RlyPreCtrl
            DSP_M_HWO_b_RlyHeatCtrl_0: accessed-variable=Pp_ASW2BSW_HWO_b_RlyHeatCtrl.HWO_b_RlyHeatCtrl
            DSP_M_HWO_e_RlyPosCtrl_0: accessed-variable=Pp_ASW2BSW_HWO_e_RlyPosCtrl.HWO_e_RlyPosCtrl
            DSP_M_HWO_b_1F0En_0: accessed-variable=Pp_ASW2BSW_HWO_b_1F0En.HWO_b_1F0En
            DSP_M_HWO_b_CMUSleepReq_0: accessed-variable=Pp_ASW2BSW_HWO_b_CMUSleepReq.HWO_b_CMUSleepReq
            DSP_M_HWO_V_CellUOverThdShtDw_0: accessed-variable=Pp_ASW2BSW_HWO_V_CellUOverThdShtDw.HWO_V_CellUOverThdShtDw
            DSP_M_HWO_b_SocSaveReq_0: accessed-variable=Pp_ASW2BSW_HWO_b_SocSaveReq.HWO_b_SocSaveReq
            DSP_M_HWO_b_BcuShtDwnReq_0: accessed-variable=Pp_ASW2BSW_HWO_b_BcuShtDwnReq.HWO_b_BcuShtDwnReq
            DSP_M_HWO_b_IsoPosSwt_0: accessed-variable=Pp_ASW2BSW_HWO_b_IsoPosSwt.HWO_b_IsoPosSwt
            DSP_M_HWO_b_IsoMinusSwt_0: accessed-variable=Pp_ASW2BSW_HWO_b_IsoMinusSwt.HWO_b_IsoMinusSwt
            DSP_M_HWO_b_IsoGndSwt_0: accessed-variable=Pp_ASW2BSW_HWO_b_IsoGndSwt.HWO_b_IsoGndSwt
            DSP_M_HWO_b_BalCtrl_0: accessed-variable=Pp_ASW2BSW_HWO_b_BalCtrl.HWO_b_BalCtrl
            DSP_M_HWO_b_CellUActv_0: accessed-variable=Pp_ASW2BSW_HWO_b_CellUActv.HWO_b_CellUActv
            DSP_M_HWO_b_CellTActv_0: accessed-variable=Pp_ASW2BSW_HWO_b_CellTActv.HWO_b_CellTActv
            DSP_M_HWO_V_CellUUnderThdShtDw_0: accessed-variable=Pp_ASW2BSW_HWO_V_CellUUnderThdShtDw.HWO_V_CellUUnderThdShtDw
            DSP_M_HWO_deC_CellTOverThdShtDw_0: accessed-variable=Pp_ASW2BSW_HWO_deC_CellTOverThdShtDw.HWO_deC_CellTOverThdShtDw
            DSP_M_AccRateArray_0: accessed-variable=Interface888.AccRateArray
      runnable R_M_ASW_R_Event
        data-receive-point-by-arguments:
          access DRPA_M_HWI_V_CellU_0: accessed-variable=Pp_BSW2ASW_HWI_V_CellU.HWI_V_CellU
package /DataTypes/ImplementationDataTypes
  70 x impl type:
    111: implementation-data-type=float32
    222: implementation-data-type=uint8
    333: implementation-data-type=uint8
    444: implementation-data-type=uint8
    AccRateArrayDataType: category=ARRAY
      element ImplementationDataTypeElement_0: array-size=12, array-size-semantics=FIXED-SIZE, implementation-data-type=AccRateType
    IdtM_AccRateType: category=STRUCTURE
      element acc: implementation-data-type=IdtM_AccType
      element rate: implementation-data-type=IdtM_RateType
    IdtM_AccType: category=STRUCTURE
      element accx: implementation-data-type=float32
      element accy: implementation-data-type=float32
      element accz: implementation-data-type=float32
    IdtM_HWERI_b_BattUVld: implementation-data-type=boolean
    IdtM_HWERI_b_CellBalErr: category=ARRAY
      element ImplementationDataTypeElement_0: array-size=208, array-size-semantics=FIXED-SIZE, implementation-data-type=boolean
    IdtM_HWERI_b_CellTShoToGnd: category=ARRAY
      element ImplementationDataTypeElement_0: array-size=78, array-size-semantics=FIXED-SIZE, implementation-data-type=boolean
    IdtM_HWERI_b_CellTShoToVccOrOp: category=ARRAY
      element ImplementationDataTypeElement_0: array-size=78, array-size-semantics=FIXED-SIZE, implementation-data-type=boolean
    IdtM_HWERI_b_CellUOverU: category=ARRAY
      element ImplementationDataTypeElement_0: array-size=208, array-size-semantics=FIXED-SIZE, implementation-data-type=boolean
    IdtM_HWERI_b_CellUUnderU: category=ARRAY
      element ImplementationDataTypeElement_0: array-size=208, array-size-semantics=FIXED-SIZE, implementation-data-type=boolean
    IdtM_HWERI_b_ChipComErr: category=ARRAY
      element ImplementationDataTypeElement_0: array-size=13, array-size-semantics=FIXED-SIZE, implementation-data-type=boolean
    IdtM_HWERI_b_SysRstErr: category=ARRAY
      element ImplementationDataTypeElement_0: array-size=13, array-size-semantics=FIXED-SIZE, implementation-data-type=boolean
    IdtM_HWI_Hz_HvilFrequency: implementation-data-type=uint16
    IdtM_HWI_Ohm_IotnR: implementation-data-type=uint16
    IdtM_HWI_Pa_BpsPressureBoard: implementation-data-type=float32
    IdtM_HWI_V_AntiExpTemp: implementation-data-type=float32
    IdtM_HWI_V_BattCurr: implementation-data-type=float32
    IdtM_HWI_V_BattCurrChk: implementation-data-type=float32
    IdtM_HWI_V_BoardT: category=ARRAY
      element ImplementationDataTypeElement_0: array-size=26, array-size-semantics=FIXED-SIZE, implementation-data-type=uint16
    IdtM_HWI_V_CellT: category=ARRAY
      element ImplementationDataTypeElement_0: array-size=78, array-size-semantics=FIXED-SIZE, implementation-data-type=uint16
    IdtM_HWI_V_CellU: category=ARRAY
      element ImplementationDataTypeElement_0: array-size=208, array-size-semantics=FIXED-SIZE, implementation-data-type=uint16
    IdtM_HWI_V_ChrgCnctAc: implementation-data-type=float32
    IdtM_HWI_V_ChrgCnctDc: implementation-data-type=float32
    IdtM_HWI_V_Crash: implementation-data-type=float32
    IdtM_HWI_V_IotnBrdVolt: implementation-data-type=float32
    IdtM_HWI_V_IsoGndRlyVolt: implementation-data-type=float32
    IdtM_HWI_V_LinkMinusU: implementation-data-type=float32
    IdtM_HWI_V_LinkPlusU: implementation-data-type=float32
    IdtM_HWI_V_ShuntNTC: implementation-data-type=float32
    IdtM_HWI_b_CellTOverT: category=ARRAY
      element ImplementationDataTypeElement_0: array-size=78, array-size-semantics=FIXED-SIZE, implementation-data-type=boolean
    IdtM_HWI_b_CellULineOpen: category=ARRAY
      element ImplementationDataTypeElement_0: array-size=208, array-size-semantics=FIXED-SIZE, implementation-data-type=uint16
    IdtM_HWI_b_IotnBrdVoltInvlid: implementation-data-type=boolean
    IdtM_HWI_b_IsoGndRlyVoltInvlid: implementation-data-type=boolean
    IdtM_HWI_b_WakeUp: implementation-data-type=boolean
    IdtM_HWI_b_WakeUpSwt: implementation-data-type=boolean
    IdtM_HWI_b_WkeUpAFE: implementation-data-type=boolean
    IdtM_HWI_b_WkeUpBPS: implementation-data-type=boolean
    IdtM_HWI_b_WkeUpBPSBoard: implementation-data-type=boolean
    IdtM_HWI_cnt_CellTCrc: category=ARRAY
      element ImplementationDataTypeElement_0: array-size=78, array-size-semantics=FIXED-SIZE, implementation-data-type=uint16
    IdtM_HWI_cnt_CellTCrcBsw: category=ARRAY
      element ImplementationDataTypeElement_0: array-size=78, array-size-semantics=FIXED-SIZE, implementation-data-type=uint8
    IdtM_HWI_cnt_CellUCntr: category=ARRAY
      element ImplementationDataTypeElement_0: array-size=208, array-size-semantics=FIXED-SIZE, implementation-data-type=uint8
    IdtM_HWI_cnt_CellUCrc: category=ARRAY
      element ImplementationDataTypeElement_0: array-size=208, array-size-semantics=FIXED-SIZE, implementation-data-type=uint16
    IdtM_HWI_cnt_CellUCrcBsw: category=ARRAY
      element ImplementationDataTypeElement_0: array-size=208, array-size-semantics=FIXED-SIZE, implementation-data-type=uint16
    IdtM_HWI_deC_ChipT: category=ARRAY
      element ImplementationDataTypeElement_0: array-size=13, array-size-semantics=FIXED-SIZE, implementation-data-type=uint16
    IdtM_HWI_e_EOLRlyCmd: category=ARRAY
      element ImplementationDataTypeElement_0: array-size=8, array-size-semantics=FIXED-SIZE, implementation-data-type=uint8
    IdtM_HWI_e_HvilDutyCycle: implementation-data-type=uint8
    IdtM_HWI_e_SilentModSt: implementation-data-type=uint8
    IdtM_HWI_e_WakeUpResRaw: implementation-data-type=uint16
    IdtM_HWI_e_hvilSt: implementation-data-type=uint8
    IdtM_HWI_inpd_flg_dataSaveOk: implementation-data-type=boolean
    IdtM_HWO_V_CellUOverThdShtDw: implementation-data-type=float32
    IdtM_HWO_V_CellUUnderThdShtDw: category=ARRAY
      element ImplementationDataTypeElement_0: array-size=208, array-size-semantics=FIXED-SIZE, implementation-data-type=boolean
    IdtM_HWO_b_1F0En: implementation-data-type=boolean
    IdtM_HWO_b_BalCtrl: category=ARRAY
      element ImplementationDataTypeElement_0: array-size=208, array-size-semantics=FIXED-SIZE, implementation-data-type=boolean
    IdtM_HWO_b_BcuShtDwnReq: implementation-data-type=boolean
    IdtM_HWO_b_CMUSleepReq: implementation-data-type=boolean
    IdtM_HWO_b_CellTActv: category=ARRAY
      element ImplementationDataTypeElement_0: array-size=78, array-size-semantics=FIXED-SIZE, implementation-data-type=boolean
    IdtM_HWO_b_CellUActv: category=ARRAY
      element ImplementationDataTypeElement_0: array-size=208, array-size-semantics=FIXED-SIZE, implementation-data-type=boolean
    IdtM_HWO_b_IsoGndSwt: implementation-data-type=boolean
    IdtM_HWO_b_IsoMinusSwt: implementation-data-type=boolean
    IdtM_HWO_b_IsoPosSwt: implementation-data-type=boolean
    IdtM_HWO_b_RlyHeatCtrl: implementation-data-type=boolean
    IdtM_HWO_b_RlyPreCtrl: implementation-data-type=boolean
    IdtM_HWO_b_SocSaveReq: implementation-data-type=boolean
    IdtM_HWO_deC_CellTOverThdShtDw: category=ARRAY
      element ImplementationDataTypeElement_0: array-size=78, array-size-semantics=FIXED-SIZE, implementation-data-type=boolean
    IdtM_HWO_e_RlyPosCtrl: implementation-data-type=uint8
    IdtM_RateType: category=STRUCTURE
      element ratex: implementation-data-type=float32
      element ratey: implementation-data-type=float32
      element ratez: implementation-data-type=float32
package /PortInterfaces
  68 x sender receiver interface:
    Pi_M_HWI_V_BattLv
      data HWI_V_BattLv: type=IdtM_HWI_V_BattLv
    Pi_M_HWI_e_RlyPosSt
      data HWI_e_RlyPosSt: type=IdtM_HWI_e_RlyPosSt
    Pi_M_HWI_e_RlyPreSt
      data HWI_e_RlyPreSt: type=IdtM_HWI_e_RlyPreSt
    Pi_M_HWI_e_RlyHeatSt
      data HWI_e_RlyHeatSt: type=IdtM_HWI_e_RlyHeatSt
    Pi_M_AccRateArray
      data AccRateArray: type=IdtM_AccRateArray
    Pi_M_AccRateType
      data AccRateType: type=IdtM_AccRateType
    Pi_M_HWERI_b_BattUVld
      data HWERI_b_BattUVld: type=IdtM_HWERI_b_BattUVld
    Pi_M_HWERI_b_CellBalErr
      data HWERI_b_CellBalErr: type=IdtM_HWERI_b_CellBalErr
    Pi_M_HWERI_b_CellTShoToGnd
      data HWERI_b_CellTShoToGnd: type=IdtM_HWERI_b_CellTShoToGnd
    Pi_M_HWERI_b_CellTShoToVccOrOp
      data HWERI_b_CellTShoToVccOrOp: type=IdtM_HWERI_b_CellTShoToVccOrOp
    Pi_M_HWERI_b_CellUOverU
      data HWERI_b_CellUOverU: type=IdtM_HWERI_b_CellUOverU
    Pi_M_HWERI_b_CellUUnderU
      data HWERI_b_CellUUnderU: type=IdtM_HWERI_b_CellUUnderU
    Pi_M_HWERI_b_ChipComErr
      data HWERI_b_ChipComErr: type=IdtM_HWERI_b_ChipComErr
    Pi_M_HWERI_b_SysRstErr
      data HWERI_b_SysRstErr: type=IdtM_HWERI_b_SysRstErr
    Pi_M_HWI_Hz_HvilFrequency
      data HWI_Hz_HvilFrequency: type=IdtM_HWI_Hz_HvilFrequency
    Pi_M_HWI_Ohm_IotnR
      data HWI_Ohm_IotnR: type=IdtM_HWI_Ohm_IotnR
    Pi_M_HWI_Pa_BpsPressureBoard
      data HWI_Pa_BpsPressureBoard: type=IdtM_HWI_Pa_BpsPressureBoard
    Pi_M_HWI_V_AntiExpTemp
      data HWI_V_AntiExpTemp: type=IdtM_HWI_V_AntiExpTemp
    Pi_M_HWI_V_BattCurr
      data HWI_V_BattCurr: type=IdtM_HWI_V_BattCurr
    Pi_M_HWI_V_BattCurrChk
      data HWI_V_BattCurrChk: type=IdtM_HWI_V_BattCurrChk
    Pi_M_HWI_V_BoardT
      data HWI_V_BoardT: type=IdtM_HWI_V_BoardT
    Pi_M_HWI_V_CellT
      data HWI_V_CellT: type=IdtM_HWI_V_CellT
    Pi_M_HWI_V_CellU
      data HWI_V_CellU: type=IdtM_HWI_V_CellU
    Pi_M_HWI_V_ChrgCnctAc
      data HWI_V_ChrgCnctAc: type=IdtM_HWI_V_ChrgCnctAc
    Pi_M_HWI_V_ChrgCnctDc
      data HWI_V_ChrgCnctDc: type=IdtM_HWI_V_ChrgCnctDc
    Pi_M_HWI_V_Crash
      data HWI_V_Crash: type=IdtM_HWI_V_Crash
    Pi_M_HWI_V_IotnBrdVolt
      data HWI_V_IotnBrdVolt: type=IdtM_HWI_V_IotnBrdVolt
    Pi_M_HWI_V_IsoGndRlyVolt
      data HWI_V_IsoGndRlyVolt: type=IdtM_HWI_V_IsoGndRlyVolt
    Pi_M_HWI_V_LinkMinusU
      data HWI_V_LinkMinusU: type=IdtM_HWI_V_LinkMinusU
    Pi_M_HWI_V_LinkPlusU
      data HWI_V_LinkPlusU: type=IdtM_HWI_V_LinkPlusU
    Pi_M_HWI_V_ShuntNTC
      data HWI_V_ShuntNTC: type=IdtM_HWI_V_ShuntNTC
    Pi_M_HWI_b_CellTOverT
      data HWI_b_CellTOverT: type=IdtM_HWI_b_CellTOverT
    Pi_M_HWI_b_CellULineOpen
      data HWI_b_CellULineOpen: type=IdtM_HWI_b_CellULineOpen
    Pi_M_HWI_b_IotnBrdVoltInvlid
      data HWI_b_IotnBrdVoltInvlid: type=IdtM_HWI_b_IotnBrdVoltInvlid
    Pi_M_HWI_b_IsoGndRlyVoltInvlid
      data HWI_b_IsoGndRlyVoltInvlid: type=IdtM_HWI_b_IsoGndRlyVoltInvlid
    Pi_M_HWI_b_WakeUp
      data HWI_b_WakeUp: type=IdtM_HWI_b_WakeUp
    Pi_M_HWI_b_WakeUpSwt
      data HWI_b_WakeUpSwt: type=IdtM_HWI_b_WakeUpSwt
    Pi_M_HWI_b_WkeUpAFE
      data HWI_b_WkeUpAFE: type=IdtM_HWI_b_WkeUpAFE
    Pi_M_HWI_b_WkeUpBPS
      data HWI_b_WkeUpBPS: type=IdtM_HWI_b_WkeUpBPS
    Pi_M_HWI_b_WkeUpBPSBoard
      data HWI_b_WkeUpBPSBoard: type=IdtM_HWI_b_WkeUpBPSBoard
    Pi_M_HWI_cnt_CellTCrc
      data HWI_cnt_CellTCrc: type=IdtM_HWI_cnt_CellTCrc
    Pi_M_HWI_cnt_CellTCrcBsw
      data HWI_cnt_CellTCrcBsw: type=IdtM_HWI_cnt_CellTCrcBsw
    Pi_M_HWI_cnt_CellUCntr
      data HWI_cnt_CellUCntr: type=IdtM_HWI_cnt_CellUCntr
    Pi_M_HWI_cnt_CellUCrc
      data HWI_cnt_CellUCrc: type=IdtM_HWI_cnt_CellUCrc
    Pi_M_HWI_cnt_CellUCrcBsw
      data HWI_cnt_CellUCrcBsw: type=IdtM_HWI_cnt_CellUCrcBsw
    Pi_M_HWI_deC_ChipT
      data HWI_deC_ChipT: type=IdtM_HWI_deC_ChipT
    Pi_M_HWI_e_EOLRlyCmd
      data HWI_e_EOLRlyCmd: type=IdtM_HWI_e_EOLRlyCmd
    Pi_M_HWI_e_HvilDutyCycle
      data HWI_e_HvilDutyCycle: type=IdtM_HWI_e_HvilDutyCycle
    Pi_M_HWI_e_SilentModSt
      data HWI_e_SilentModSt: type=IdtM_HWI_e_SilentModSt
    Pi_M_HWI_e_WakeUpResRaw
      data HWI_e_WakeUpResRaw: type=IdtM_HWI_e_WakeUpResRaw
    Pi_M_HWI_e_hvilSt
      data HWI_e_hvilSt: type=IdtM_HWI_e_hvilSt
    Pi_M_HWI_inpd_flg_dataSaveOk
      data HWI_inpd_flg_dataSaveOk: type=IdtM_HWI_inpd_flg_dataSaveOk
    Pi_M_HWO_V_CellUOverThdShtDw
      data HWO_V_CellUOverThdShtDw: type=IdtM_HWO_V_CellUOverThdShtDw
    Pi_M_HWO_V_CellUUnderThdShtDw
      data HWO_V_CellUUnderThdShtDw: type=IdtM_HWO_V_CellUUnderThdShtDw
    Pi_M_HWO_b_1F0En
      data HWO_b_1F0En: type=IdtM_HWO_b_1F0En
    Pi_M_HWO_b_BalCtrl
      data HWO_b_BalCtrl: type=IdtM_HWO_b_BalCtrl
    Pi_M_HWO_b_BcuShtDwnReq
      data HWO_b_BcuShtDwnReq: type=IdtM_HWO_b_BcuShtDwnReq
    Pi_M_HWO_b_CMUSleepReq
      data HWO_b_CMUSleepReq: type=IdtM_HWO_b_CMUSleepReq
    Pi_M_HWO_b_CellTActv
      data HWO_b_CellTActv: type=IdtM_HWO_b_CellTActv
    Pi_M_HWO_b_CellUActv
      data HWO_b_CellUActv: type=IdtM_HWO_b_CellUActv
    Pi_M_HWO_b_IsoGndSwt
      data HWO_b_IsoGndSwt: type=IdtM_HWO_b_IsoGndSwt
    Pi_M_HWO_b_IsoMinusSwt
      data HWO_b_IsoMinusSwt: type=IdtM_HWO_b_IsoMinusSwt
    Pi_M_HWO_b_IsoPosSwt
      data HWO_b_IsoPosSwt: type=IdtM_HWO_b_IsoPosSwt
    Pi_M_HWO_b_RlyHeatCtrl
      data HWO_b_RlyHeatCtrl: type=IdtM_HWO_b_RlyHeatCtrl
    Pi_M_HWO_b_RlyPreCtrl
      data HWO_b_RlyPreCtrl: type=IdtM_HWO_b_RlyPreCtrl
    Pi_M_HWO_b_SocSaveReq
      data HWO_b_SocSaveReq: type=IdtM_HWO_b_SocSaveReq
    Pi_M_HWO_deC_CellTOverThdShtDw
      data HWO_deC_CellTOverThdShtDw: type=IdtM_HWO_deC_CellTOverThdShtDw
    Pi_M_HWO_e_RlyPosCtrl
      data HWO_e_RlyPosCtrl: type=IdtM_HWO_e_RlyPosCtrl
